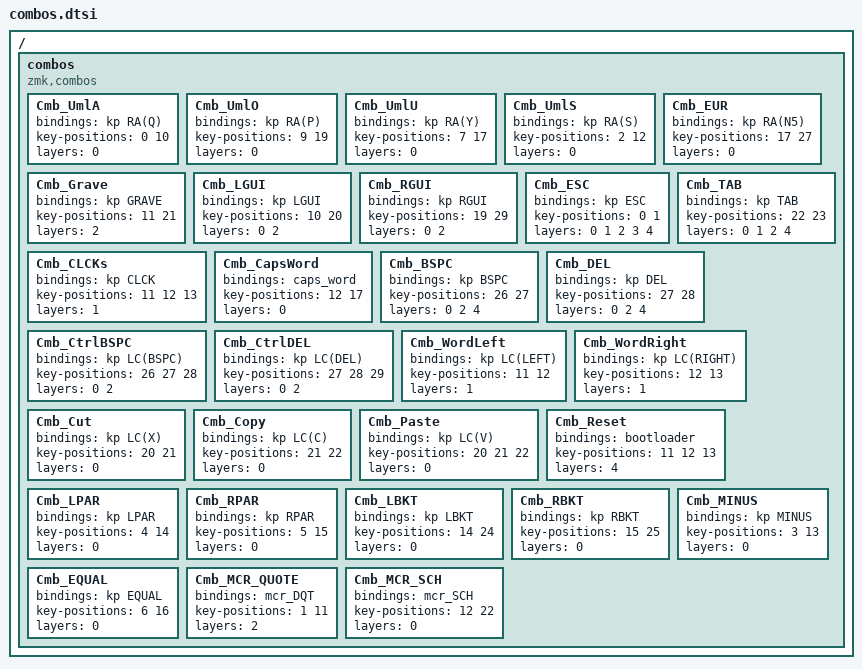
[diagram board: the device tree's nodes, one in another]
/ {

    combos {
        compatible = "zmk,combos";

        Cmb_UmlA {
            bindings = <&kp RA(Q)>;
            key-positions = <0 10>;
            layers = <0>;
        };

        Cmb_UmlO {
            bindings = <&kp RA(P)>;
            key-positions = <9 19>;
            layers = <0>;
        };

        Cmb_UmlU {
            bindings = <&kp RA(Y)>;
            key-positions = <7 17>;
            layers = <0>;
        };

        Cmb_UmlS {
            bindings = <&kp RA(S)>;
            key-positions = <2 12>;
            layers = <0>;
        };

        Cmb_EUR {
            bindings = <&kp RA(N5)>;
            key-positions = <17 27>;
            layers = <0>;
        };

        Cmb_Grave {
            bindings = <&kp GRAVE>;
            key-positions = <11 21>;
            layers = <2>;
        };

        Cmb_LGUI {
            bindings = <&kp LGUI>;
            key-positions = <10 20>;
            layers = <0 2>;
        };

        Cmb_RGUI {
            bindings = <&kp RGUI>;
            key-positions = <19 29>;
            layers = <0 2>;
        };

        Cmb_ESC {
            bindings = <&kp ESC>;
            key-positions = <0 1>;
            layers = <0 1 2 3 4>;
        };

        Cmb_TAB {
            bindings = <&kp TAB>;
            key-positions = <22 23>;
            layers = <0 1 2 4>;
        };

        Cmb_CLCKs {
            bindings = <&kp CLCK>;
            key-positions = <11 12 13>;
            layers = <1>;
        };

        Cmb_CapsWord {
            bindings = <&caps_word>;
            key-positions = <12 17>;
            layers = <0>;
        };

        Cmb_BSPC {
            bindings = <&kp BSPC>;
            key-positions = <26 27>;
            layers = <0 2 4>;
        };

        Cmb_DEL {
            bindings = <&kp DEL>;
            key-positions = <27 28>;
            layers = <0 2 4>;
        };

        Cmb_CtrlBSPC {
            bindings = <&kp LC(BSPC)>;
            key-positions = <26 27 28>;
            layers = <0 2>;
        };

        Cmb_CtrlDEL {
            bindings = <&kp LC(DEL)>;
            key-positions = <27 28 29>;
            layers = <0 2>;
        };

        Cmb_WordLeft {
            bindings = <&kp LC(LEFT)>;
            key-positions = <11 12>;
            layers = <1>;
        };

        Cmb_WordRight {
            bindings = <&kp LC(RIGHT)>;
            key-positions = <12 13>;
            layers = <1>;
        };

        Cmb_Cut {
            bindings = <&kp LC(X)>;
            key-positions = <20 21>;
            layers = <0>;
        };

        Cmb_Copy {
            bindings = <&kp LC(C)>;
            key-positions = <21 22>;
            layers = <0>;
        };

        Cmb_Paste {
            bindings = <&kp LC(V)>;
            key-positions = <20 21 22>;
            layers = <0>;
        };

        Cmb_Reset {
            bindings = <&bootloader>;
            key-positions = <11 12 13>;
            layers = <4>;
        };

        Cmb_LPAR {
            bindings = <&kp LPAR>;
            key-positions = <4 14>;
            layers = <0>;
        };

        Cmb_RPAR {
            bindings = <&kp RPAR>;
            key-positions = <5 15>;
            layers = <0>;
        };

        Cmb_LBKT {
            bindings = <&kp LBKT>;
            key-positions = <14 24>;
            layers = <0>;
        };

        Cmb_RBKT {
            bindings = <&kp RBKT>;
            key-positions = <15 25>;
            layers = <0>;
        };

        Cmb_MINUS {
            bindings = <&kp MINUS>;
            key-positions = <3 13>;
            layers = <0>;
        };

        Cmb_EQUAL {
            bindings = <&kp EQUAL>;
            key-positions = <6 16>;
            layers = <0>;
        };

        Cmb_MCR_QUOTE {
            bindings = <&mcr_DQT>;
            key-positions = <1 11>;
            layers = <2>;
        };

        Cmb_MCR_SCH {
            bindings = <&mcr_SCH>;
            key-positions = <12 22>;
            layers = <0>;
        };
    };
};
